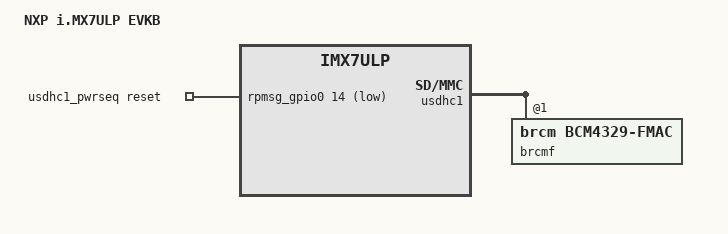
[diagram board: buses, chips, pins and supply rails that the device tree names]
/*
 * Copyright 2019 NXP
 *
 * This program is free software; you can redistribute it and/or modify
 * it under the terms of the GNU General Public License version 2 as
 * published by the Free Software Foundation.
 */

#include "imx7ulp-evk.dts"

/ {
	model = "NXP i.MX7ULP EVKB";
	compatible = "fsl,imx7ulp-evkb", "fsl,imx7ulp", "Generic DT based system";

	regulators {
		reg_sd1_vmmc: sd1_regulator {
			status = "disabled";
		};
	};

	usdhc1_pwrseq: usdhc1_pwrseq {
		compatible = "mmc-pwrseq-simple";
		reset-gpios = <&rpmsg_gpio0 14 GPIO_ACTIVE_LOW>;
		post-power-on-delay-ms = <80>;
	};
};

&usdhc1 {
	#address-cells = <1>;
	#size-cells = <0>;
	/delete-property/ vmmc-supply;
	mmc-pwrseq = <&usdhc1_pwrseq>;
	cap-power-off-card;

	brcmf: bcrmf@1 {
		reg = <1>;
		compatible = "brcm,bcm4329-fmac";
	};
};
